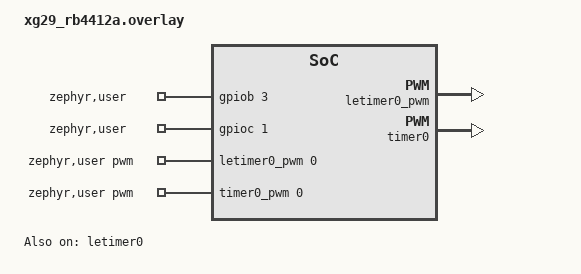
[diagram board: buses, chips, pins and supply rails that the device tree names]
/*
 * Copyright (c) 2025 Silicon Laboratories Inc.
 *
 * SPDX-License-Identifier: Apache-2.0
 */

#include <zephyr/dt-bindings/pwm/pwm.h>

/* Connections:
 * EXP15 - EXP16: LETIMER (PB2) to GPIO (PB3)
 * EXP4 - EXP6: TIMER (PC0) to GPIO (PC1)
 */

/ {
	zephyr,user {
		pwms = <&letimer0_pwm 0 PWM_MSEC(5) PWM_POLARITY_NORMAL>,
		       <&timer0_pwm 0 PWM_MSEC(5) PWM_POLARITY_NORMAL>;
		gpios = <&gpiob 3 GPIO_ACTIVE_HIGH>, <&gpioc 1 GPIO_ACTIVE_HIGH>;
	};
};

&pinctrl {
	letimer0_default: letimer0_default {
		group1 {
			pins = <LETIMER0_OUT0_PB2>;
			drive-push-pull;
		};
	};

	timer0_default: timer0_default {
		group1 {
			pins = <TIMER0_CC0_PC0>;
			drive-push-pull;
		};
	};
};

&letimer0 {
	status = "okay";

	letimer0_pwm: pwm {
		pinctrl-0 = <&letimer0_default>;
		pinctrl-names = "default";
		status = "okay";
	};
};

&timer0 {
	status = "okay";

	timer0_pwm: pwm {
		pinctrl-0 = <&timer0_default>;
		pinctrl-names = "default";
		status = "okay";
	};
};
